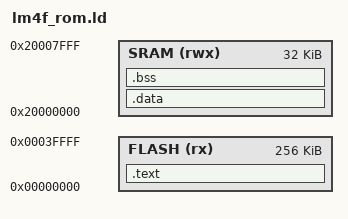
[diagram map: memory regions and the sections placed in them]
/******************************************************************************
 *
 * lm4f_rom.ld - Linker configuration file for project.
 *
 * Copyright (c) 2011 Texas Instruments Incorporated.  All rights reserved.
 * Software License Agreement
 * 
 * Texas Instruments (TI) is supplying this software for use solely and
 * exclusively on TI's microcontroller products. The software is owned by
 * TI and/or its suppliers, and is protected under applicable copyright
 * laws. You may not combine this software with "viral" open-source
 * software in order to form a larger program.
 * 
 * THIS SOFTWARE IS PROVIDED "AS IS" AND WITH ALL FAULTS.
 * NO WARRANTIES, WHETHER EXPRESS, IMPLIED OR STATUTORY, INCLUDING, BUT
 * NOT LIMITED TO, IMPLIED WARRANTIES OF MERCHANTABILITY AND FITNESS FOR
 * A PARTICULAR PURPOSE APPLY TO THIS SOFTWARE. TI SHALL NOT, UNDER ANY
 * CIRCUMSTANCES, BE LIABLE FOR SPECIAL, INCIDENTAL, OR CONSEQUENTIAL
 * DAMAGES, FOR ANY REASON WHATSOEVER.
 * 
 * This is part of revision 8264 of the EK-LM4F232 Firmware Package.
 *
 *****************************************************************************/

/* Program Entry, set to mark it as "used" and avoid gc */
MEMORY
{
    FLASH (rx) : ORIGIN = 0x00000000, LENGTH = 0x00040000
    SRAM (rwx) : ORIGIN = 0x20000000, LENGTH = 0x00008000
}

SECTIONS
{
    .text :
    {
        _text = .;
        KEEP(*(.isr_vector))
        *(.text*)
        *(.rodata*)
        _etext = .;

        /* section information for finsh shell */
        . = ALIGN(4);
        __fsymtab_start = .;
        KEEP(*(FSymTab))
        __fsymtab_end = .;
        . = ALIGN(4);
        __vsymtab_start = .;
        KEEP(*(VSymTab))
        __vsymtab_end = .;
        . = ALIGN(4);

        . = ALIGN(4);
        __rt_init_start = .;
        KEEP(*(SORT(.rti_fn*)))
        __rt_init_end = .;
        . = ALIGN(4);

    } > FLASH

    .data : AT(ADDR(.text) + SIZEOF(.text))
    {
        _data = .;
        *(vtable)
        *(.data*)
        _edata = .;
    } > SRAM

    .bss :
    {
        _bss = .;
        *(.bss*)
        *(COMMON)
        _ebss = .;
    } > SRAM

    __bss_end = .;

}
